# iostr730 register map
Registers are 16-bit, access not given, no defined reset value unless marked. A register's access mark holds for its fields unless they carry their own. Addresses are absolute; registers are grouped by the start of their names; [hi:lo] are bit positions; {n}, {i} and the like mark numbered series.

## DMA0
{0xFFFFF000+0x40*i} DMA0_SOURCEL{i} (i=0..3)
{0xFFFFF004+0x40*i} DMA0_SOURCEH{i} (i=0..3)
{0xFFFFF008+0x40*i} DMA0_DESTL{i} (i=0..3)
{0xFFFFF00C+0x40*i} DMA0_DESTH{i} (i=0..3)
{0xFFFFF010+0x40*i} DMA0_MAX{i} (i=0..3)
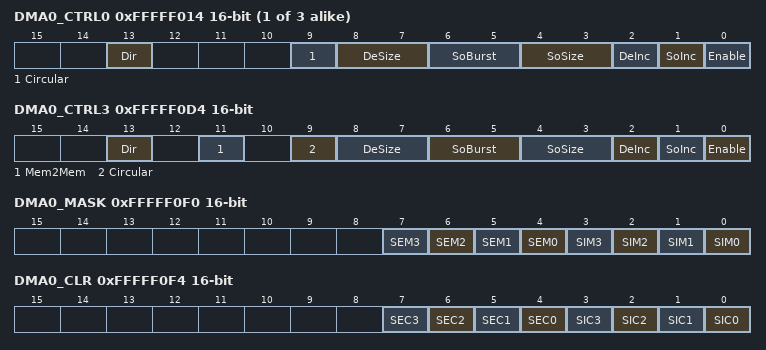
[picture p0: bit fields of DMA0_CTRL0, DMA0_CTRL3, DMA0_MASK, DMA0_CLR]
{0xFFFFF014+0x40*i} DMA0_CTRL{i} (i=0..2)
  [13] Dir, [9] Circular, [8:7] DeSize, [6:5] SoBurst, [4:3] SoSize, [2] DeInc, [1] SoInc, [0] Enable
{0xFFFFF018+0x40*i} DMA0_SOCURRH{i} (i=0..3)
{0xFFFFF01C+0x40*i} DMA0_SOCURRL{i} (i=0..3)
{0xFFFFF020+0x40*i} DMA0_DECURRH{i} (i=0..3)
{0xFFFFF024+0x40*i} DMA0_DECURRL{i} (i=0..3)
{0xFFFFF028+0x40*i} DMA0_TCNT{i} (i=0..3)
{0xFFFFF02C+0x40*i} DMA0_LUBuff{i} (i=0..3)
0xFFFFF0D4 DMA0_CTRL3
  [13] Dir, [11] Mem2Mem, [9] Circular, [8:7] DeSize, [6:5] SoBurst, [4:3] SoSize, [2] DeInc, [1] SoInc, [0] Enable
0xFFFFF0F0 DMA0_MASK
  [n+4] SEM{n} (n=0..3), [n] SIM{n} (n=0..3)
0xFFFFF0F4 DMA0_CLR
  [n+4] SEC{n} (n=0..3), [n] SIC{n} (n=0..3)
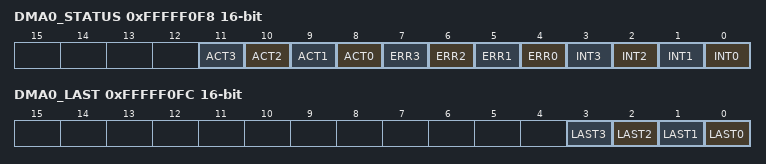
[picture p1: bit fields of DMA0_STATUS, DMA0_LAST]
0xFFFFF0F8 DMA0_STATUS
  [n+8] ACT{n} (n=0..3), [n+4] ERR{n} (n=0..3), [n] INT{n} (n=0..3)
0xFFFFF0FC DMA0_LAST
  [n] LAST{n} (n=0..3)

## DMA1
{0xFFFFF100+0x40*i} DMA1_SOURCEL{i} (i=0..3)
{0xFFFFF104+0x40*i} DMA1_SOURCEH{i} (i=0..3)
{0xFFFFF108+0x40*i} DMA1_DESTL{i} (i=0..3)
{0xFFFFF10C+0x40*i} DMA1_DESTH{i} (i=0..3)
{0xFFFFF110+0x40*i} DMA1_MAX{i} (i=0..3)
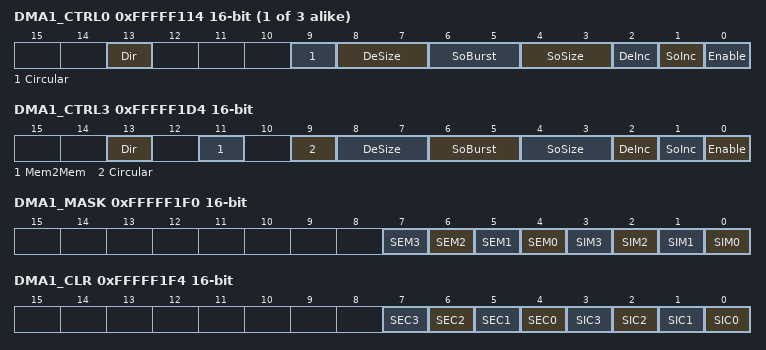
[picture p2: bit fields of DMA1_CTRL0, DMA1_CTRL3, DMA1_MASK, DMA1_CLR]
{0xFFFFF114+0x40*i} DMA1_CTRL{i} (i=0..2)
  [13] Dir, [9] Circular, [8:7] DeSize, [6:5] SoBurst, [4:3] SoSize, [2] DeInc, [1] SoInc, [0] Enable
{0xFFFFF118+0x40*i} DMA1_SOCURRH{i} (i=0..3)
{0xFFFFF11C+0x40*i} DMA1_SOCURRL{i} (i=0..3)
{0xFFFFF120+0x40*i} DMA1_DECURRH{i} (i=0..3)
{0xFFFFF124+0x40*i} DMA1_DECURRL{i} (i=0..3)
{0xFFFFF128+0x40*i} DMA1_TCNT{i} (i=0..3)
{0xFFFFF12C+0x40*i} DMA1_LUBuff{i} (i=0..3)
0xFFFFF1D4 DMA1_CTRL3
  [13] Dir, [11] Mem2Mem, [9] Circular, [8:7] DeSize, [6:5] SoBurst, [4:3] SoSize, [2] DeInc, [1] SoInc, [0] Enable
0xFFFFF1F0 DMA1_MASK
  [n+4] SEM{n} (n=0..3), [n] SIM{n} (n=0..3)
0xFFFFF1F4 DMA1_CLR
  [n+4] SEC{n} (n=0..3), [n] SIC{n} (n=0..3)
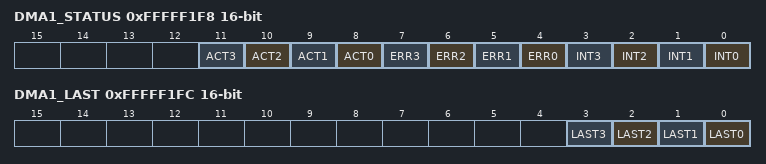
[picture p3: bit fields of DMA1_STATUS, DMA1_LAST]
0xFFFFF1F8 DMA1_STATUS
  [n+8] ACT{n} (n=0..3), [n+4] ERR{n} (n=0..3), [n] INT{n} (n=0..3)
0xFFFFF1FC DMA1_LAST
  [n] LAST{n} (n=0..3)

## DMA2
{0xFFFFF200+0x40*i} DMA2_SOURCEL{i} (i=0..3)
{0xFFFFF204+0x40*i} DMA2_SOURCEH{i} (i=0..3)
{0xFFFFF208+0x40*i} DMA2_DESTL{i} (i=0..3)
{0xFFFFF20C+0x40*i} DMA2_DESTH{i} (i=0..3)
{0xFFFFF210+0x40*i} DMA2_MAX{i} (i=0..3)
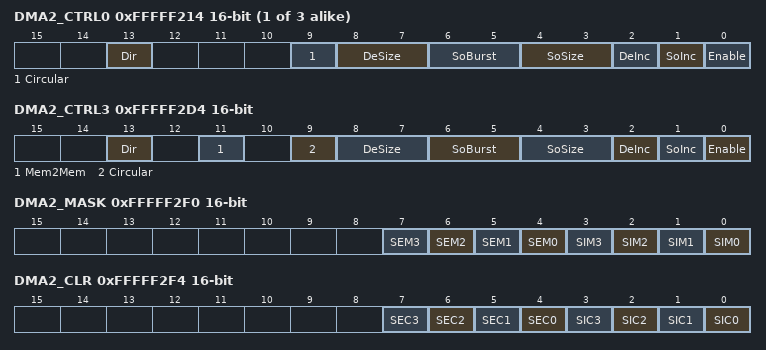
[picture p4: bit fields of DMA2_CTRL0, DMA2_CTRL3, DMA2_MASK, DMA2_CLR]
{0xFFFFF214+0x40*i} DMA2_CTRL{i} (i=0..2)
  [13] Dir, [9] Circular, [8:7] DeSize, [6:5] SoBurst, [4:3] SoSize, [2] DeInc, [1] SoInc, [0] Enable
{0xFFFFF218+0x40*i} DMA2_SOCURRH{i} (i=0..3)
{0xFFFFF21C+0x40*i} DMA2_SOCURRL{i} (i=0..3)
{0xFFFFF220+0x40*i} DMA2_DECURRH{i} (i=0..3)
{0xFFFFF224+0x40*i} DMA2_DECURRL{i} (i=0..3)
{0xFFFFF228+0x40*i} DMA2_TCNT{i} (i=0..3)
{0xFFFFF22C+0x40*i} DMA2_LUBuff{i} (i=0..3)
0xFFFFF2D4 DMA2_CTRL3
  [13] Dir, [11] Mem2Mem, [9] Circular, [8:7] DeSize, [6:5] SoBurst, [4:3] SoSize, [2] DeInc, [1] SoInc, [0] Enable
0xFFFFF2F0 DMA2_MASK
  [n+4] SEM{n} (n=0..3), [n] SIM{n} (n=0..3)
0xFFFFF2F4 DMA2_CLR
  [n+4] SEC{n} (n=0..3), [n] SIC{n} (n=0..3)
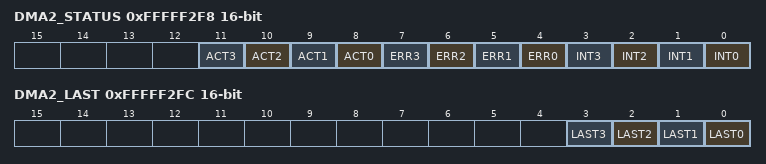
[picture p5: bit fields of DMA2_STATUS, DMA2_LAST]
0xFFFFF2F8 DMA2_STATUS
  [n+8] ACT{n} (n=0..3), [n+4] ERR{n} (n=0..3), [n] INT{n} (n=0..3)
0xFFFFF2FC DMA2_LAST
  [n] LAST{n} (n=0..3)

## DMA3
{0xFFFFF300+0x40*i} DMA3_SOURCEL{i} (i=0..3)
{0xFFFFF304+0x40*i} DMA3_SOURCEH{i} (i=0..3)
{0xFFFFF308+0x40*i} DMA3_DESTL{i} (i=0..3)
{0xFFFFF30C+0x40*i} DMA3_DESTH{i} (i=0..3)
{0xFFFFF310+0x40*i} DMA3_MAX{i} (i=0..3)
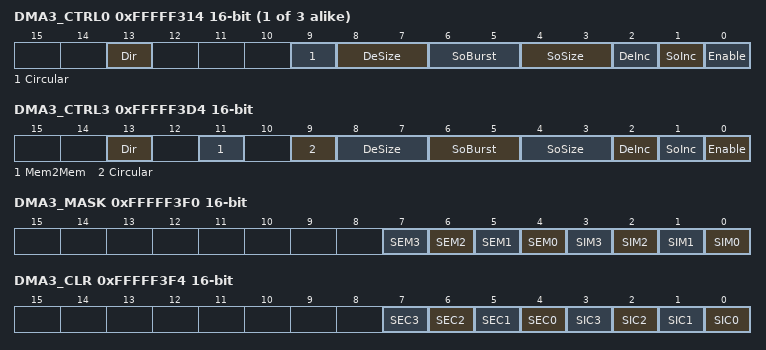
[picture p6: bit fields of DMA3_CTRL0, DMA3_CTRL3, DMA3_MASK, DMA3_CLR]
{0xFFFFF314+0x40*i} DMA3_CTRL{i} (i=0..2)
  [13] Dir, [9] Circular, [8:7] DeSize, [6:5] SoBurst, [4:3] SoSize, [2] DeInc, [1] SoInc, [0] Enable
{0xFFFFF318+0x40*i} DMA3_SOCURRH{i} (i=0..3)
{0xFFFFF31C+0x40*i} DMA3_SOCURRL{i} (i=0..3)
{0xFFFFF320+0x40*i} DMA3_DECURRH{i} (i=0..3)
{0xFFFFF324+0x40*i} DMA3_DECURRL{i} (i=0..3)
{0xFFFFF328+0x40*i} DMA3_TCNT{i} (i=0..3)
{0xFFFFF32C+0x40*i} DMA3_LUBuff{i} (i=0..3)
0xFFFFF3D4 DMA3_CTRL3
  [13] Dir, [11] Mem2Mem, [9] Circular, [8:7] DeSize, [6:5] SoBurst, [4:3] SoSize, [2] DeInc, [1] SoInc, [0] Enable
0xFFFFF3F0 DMA3_MASK
  [n+4] SEM{n} (n=0..3), [n] SIM{n} (n=0..3)
0xFFFFF3F4 DMA3_CLR
  [n+4] SEC{n} (n=0..3), [n] SIC{n} (n=0..3)
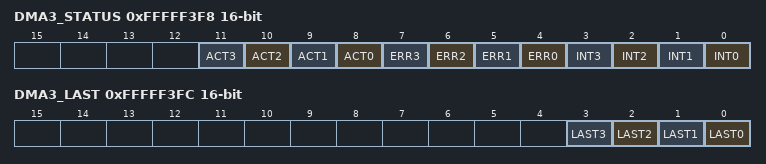
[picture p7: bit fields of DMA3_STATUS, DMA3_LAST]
0xFFFFF3F8 DMA3_STATUS
  [n+8] ACT{n} (n=0..3), [n+4] ERR{n} (n=0..3), [n] INT{n} (n=0..3)
0xFFFFF3FC DMA3_LAST
  [n] LAST{n} (n=0..3)

## RTC
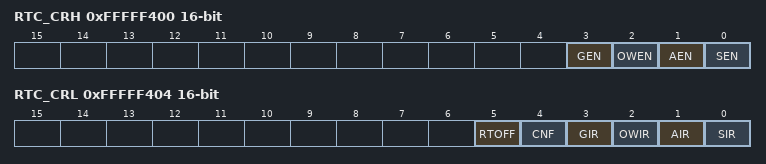
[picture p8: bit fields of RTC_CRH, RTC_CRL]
0xFFFFF400 RTC_CRH
  [3] GEN, [2] OWEN, [1] AEN, [0] SEN
0xFFFFF404 RTC_CRL
  [5] RTOFF, [4] CNF, [3] GIR, [2] OWIR, [1] AIR, [0] SIR
0xFFFFF408 RTC_PRLH
  [3:0] PRSL
0xFFFFF40C RTC_PRLL
0xFFFFF410 RTC_DIVH
  [3:0] DIV
0xFFFFF414 RTC_DIVL
0xFFFFF418 RTC_CNTH
0xFFFFF41C RTC_CNTL
0xFFFFF420 RTC_ALRH
0xFFFFF424 RTC_ALRL

## CMU
0xFFFFF600 CMU_RCCTL
  [3:0] RCCTL
0xFFFFF604 CMU_FDISP
  [11:0] FD
0xFFFFF608 CMU_FRH
  [11:0] FH
0xFFFFF60C CMU_FRL
  [11:0] FL
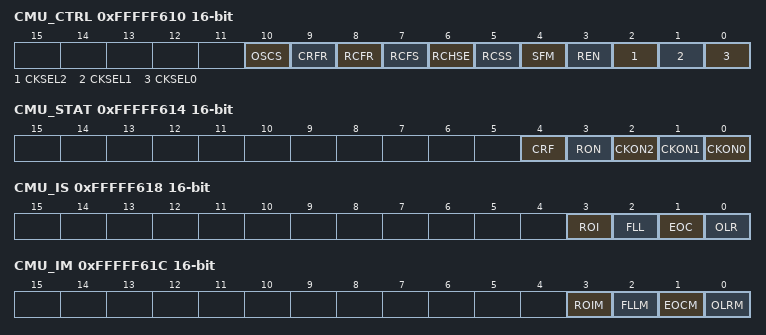
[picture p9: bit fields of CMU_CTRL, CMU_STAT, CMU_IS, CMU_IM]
0xFFFFF610 CMU_CTRL
  [10] OSCS, [9] CRFR, [8] RCFR, [7] RCFS, [6] RCHSE, [5] RCSS, [4] SFM, [3] REN, [2] CKSEL2, [1] CKSEL1, [0] CKSEL0
0xFFFFF614 CMU_STAT
  [4] CRF, [3] RON, [2] CKON2, [1] CKON1, [0] CKON0
0xFFFFF618 CMU_IS
  [3] ROI, [2] FLL, [1] EOC, [0] OLR
0xFFFFF61C CMU_IM
  [3] ROIM, [2] FLLM, [1] EOCM, [0] OLRM
0xFFFFF620 CMU_EOCV
  [7:0] EOCV
0xFFFFF624 CMU_WE

## ADC
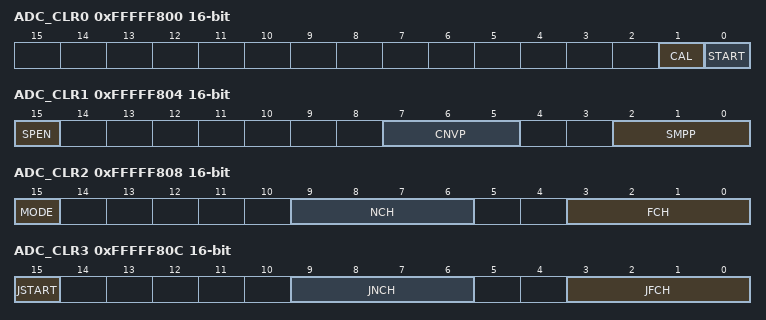
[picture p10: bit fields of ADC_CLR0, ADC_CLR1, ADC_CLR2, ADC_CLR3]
0xFFFFF800 ADC_CLR0
  [1] CAL, [0] START
0xFFFFF804 ADC_CLR1
  [15] SPEN, [7:5] CNVP, [2:0] SMPP
0xFFFFF808 ADC_CLR2
  [15] MODE, [9:6] NCH, [3:0] FCH
0xFFFFF80C ADC_CLR3
  [15] JSTART, [9:6] JNCH, [3:0] JFCH
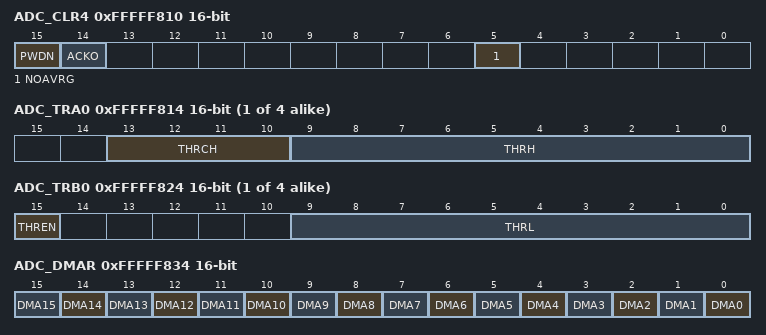
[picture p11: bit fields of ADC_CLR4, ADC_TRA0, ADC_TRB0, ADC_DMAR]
0xFFFFF810 ADC_CLR4
  [15] PWDN, [14] ACKO, [5] NOAVRG
{0xFFFFF814+4i} ADC_TRA{i} (i=0..3)
  [13:10] THRCH, [9:0] THRH
{0xFFFFF824+4i} ADC_TRB{i} (i=0..3)
  [15] THREN, [9:0] THRL
0xFFFFF834 ADC_DMAR
  [n] DMA{n} (n=0..15)
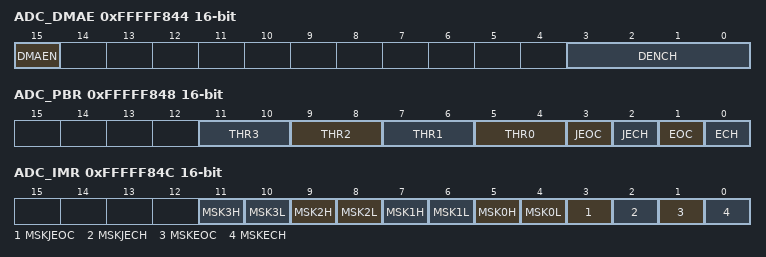
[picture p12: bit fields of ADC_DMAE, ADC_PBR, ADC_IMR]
0xFFFFF844 ADC_DMAE
  [15] DMAEN, [3:0] DENCH
0xFFFFF848 ADC_PBR
  [2n+5:2n+4] THR{n} (n=0..3), [3] JEOC, [2] JECH, [1] EOC, [0] ECH
0xFFFFF84C ADC_IMR
  [2n+5] MSK{n}H (n=0..3), [2n+4] MSK{n}L (n=0..3), [3] MSKJEOC, [2] MSKJECH, [1] MSKEOC, [0] MSKECH
{0xFFFFF850+4i} ADC_D{i} (i=0..15)
  [9:0] CDATA

## EIC
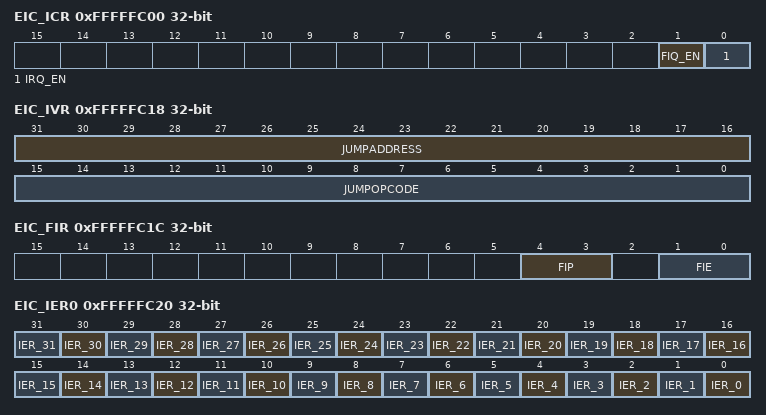
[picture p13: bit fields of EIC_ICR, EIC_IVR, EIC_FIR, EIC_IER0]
0xFFFFFC00 EIC_ICR 32-bit
  [1] FIQ_EN, [0] IRQ_EN
0xFFFFFC04 EIC_CICR 32-bit
  [5:0] CIC
0xFFFFFC08 EIC_CIPR 32-bit
  [3:0] CIP
0xFFFFFC10 EIC_FIER 32-bit
  [1:0] FIE
0xFFFFFC14 EIC_FIPR 32-bit
  [1:0] FIP
0xFFFFFC18 EIC_IVR 32-bit
  [31:16] JUMPADDRESS, [15:0] JUMPOPCODE
0xFFFFFC1C EIC_FIR 32-bit
  [4:3] FIP, [1:0] FIE
0xFFFFFC20 EIC_IER0 32-bit
  [n] IER_{n} (n=0..31)
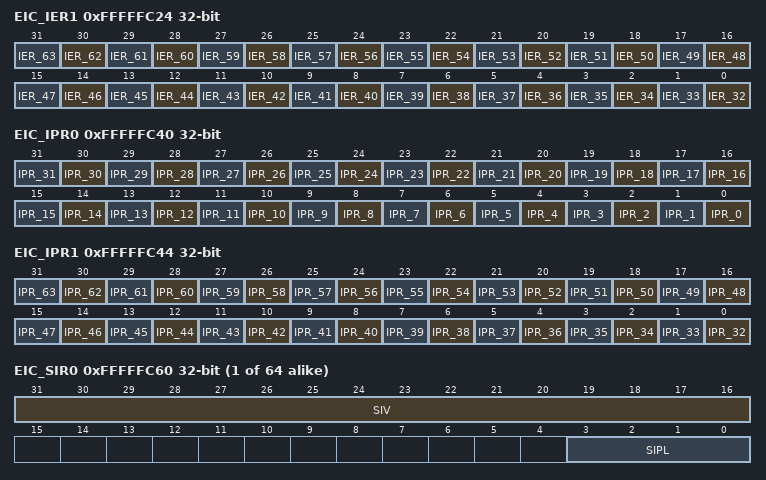
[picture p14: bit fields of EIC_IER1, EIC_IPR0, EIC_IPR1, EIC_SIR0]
0xFFFFFC24 EIC_IER1 32-bit
  [n-32] IER_{n} (n=32..63)
0xFFFFFC40 EIC_IPR0 32-bit
  [n] IPR_{n} (n=0..31)
0xFFFFFC44 EIC_IPR1 32-bit
  [n-32] IPR_{n} (n=32..63)
{0xFFFFFC60+4i} EIC_SIR{i} 32-bit (i=0..63)
  [31:16] SIV, [3:0] SIPL
